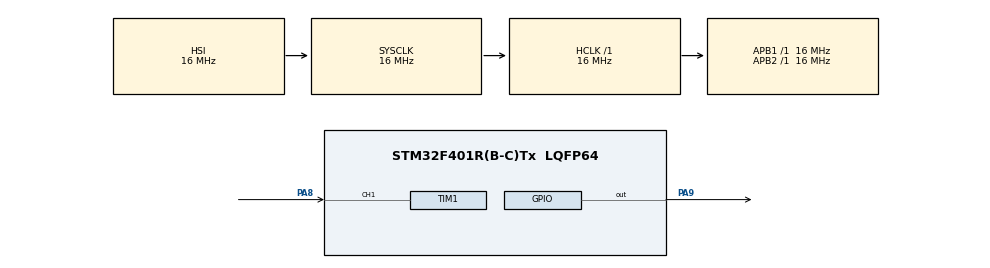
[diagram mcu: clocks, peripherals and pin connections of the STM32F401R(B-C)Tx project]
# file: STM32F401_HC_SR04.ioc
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Mcu.Family=STM32F4
Mcu.Name=STM32F401R(B-C)Tx
Mcu.Package=LQFP64
NVIC.PriorityGroup=NVIC_PRIORITYGROUP_4
NVIC.TIM1_CC_IRQn=true\:0\:0\:false\:false\:true\:true\:true\:true
PA13.Mode=Serial_Wire
PA13.Signal=SYS_JTMS-SWDIO
PA14.Mode=Serial_Wire
PA14.Signal=SYS_JTCK-SWCLK
PA8.Signal=S_TIM1_CH1
PA9.Signal=GPIO_Output
ProjectManager.HeapSize=0x200
ProjectManager.StackSize=0x400
ProjectManager.TargetToolchain=MDK-ARM V5.32
RCC.AHBFreq_Value=16000000
RCC.APB1Freq_Value=16000000
RCC.APB2Freq_Value=16000000
RCC.CortexFreq_Value=16000000
RCC.HSE_VALUE=25000000
RCC.HSI_VALUE=16000000
RCC.LSE_VALUE=32768
RCC.SYSCLKFreq_VALUE=16000000
RCC.VCOOutputFreq_Value=192000000
SH.S_TIM1_CH1.0=TIM1_CH1,Input_Capture1_from_TI1
SH.S_TIM1_CH1.1=TIM1_CH1,TriggerSource_TI1FP1
TIM1.Channel-Input_Capture1_from_TI1=TIM_CHANNEL_1
TIM1.Channel-Input_Capture2_from_TI1_63=TIM_CHANNEL_2
TIM1.ICPolarity_CH2=TIM_INPUTCHANNELPOLARITY_FALLING
TIM1.Prescaler=15
VP_TIM1_VS_ClockSourceINT.Mode=Internal
VP_TIM1_VS_ControllerModeReset.Mode=Reset Mode
VP_TIM1_VS_indirect_ch1.Mode=Input_Capture2_from_TI1_63
board=custom

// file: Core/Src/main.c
/* USER CODE BEGIN Header */
/**
  ******************************************************************************
  * @file           : main.c
  * @brief          : Main program body
  ******************************************************************************
  * @attention
  *
  * Copyright (c) 2025 STMicroelectronics.
  * All rights reserved.
  *
  * This software is licensed under terms that can be found in the LICENSE file
  * in the root directory of this software component.
  * If no LICENSE file comes with this software, it is provided AS-IS.
  *
  ******************************************************************************
  */
/* USER CODE END Header */
#include "main.h"
#include "tim.h"
#include "gpio.h"

/* USER CODE BEGIN Includes */
#include "hcsr04.h"
/* USER CODE END Includes */

void SystemClock_Config(void);
/* USER CODE BEGIN PFP */
void HAL_TIM_IC_CaptureCallback(TIM_HandleTypeDef *htim);
/* USER CODE END PFP */

int main(void)
{

  /* MCU Configuration--------------------------------------------------------*/

  /* Reset of all peripherals, Initializes the Flash interface and the Systick. */
  HAL_Init();

  /* Configure the system clock */
  SystemClock_Config();

  /* Initialize all configured peripherals */
  MX_GPIO_Init();
  MX_TIM1_Init();

  /* Infinite loop */
  /* USER CODE BEGIN WHILE */

	hcsr04_init(&htim1, GPIOA, GPIO_PIN_9, 1);
  while (1)
  {
		hcsr04_triger();
		volatile float data = hcsr04_get_cm(1000000 /* Freq that used to caculate distance*/);

    /* USER CODE END WHILE */

  }
}

void SystemClock_Config(void)
{
  RCC_OscInitTypeDef RCC_OscInitStruct = {0};
  RCC_ClkInitTypeDef RCC_ClkInitStruct = {0};

  /** Configure the main internal regulator output voltage
  */
  __HAL_RCC_PWR_CLK_ENABLE();
  __HAL_PWR_VOLTAGESCALING_CONFIG(PWR_REGULATOR_VOLTAGE_SCALE2);

  /** Initializes the RCC Oscillators according to the specified parameters
  * in the RCC_OscInitTypeDef structure.
  */
  RCC_OscInitStruct.OscillatorType = RCC_OSCILLATORTYPE_HSI;
  RCC_OscInitStruct.HSIState = RCC_HSI_ON;
  RCC_OscInitStruct.HSICalibrationValue = RCC_HSICALIBRATION_DEFAULT;
  RCC_OscInitStruct.PLL.PLLState = RCC_PLL_NONE;
  if (HAL_RCC_OscConfig(&RCC_OscInitStruct) != HAL_OK)
  {
    Error_Handler();
  }

  /** Initializes the CPU, AHB and APB buses clocks
  */
  RCC_ClkInitStruct.ClockType = RCC_CLOCKTYPE_HCLK|RCC_CLOCKTYPE_SYSCLK
                              |RCC_CLOCKTYPE_PCLK1|RCC_CLOCKTYPE_PCLK2;
  RCC_ClkInitStruct.SYSCLKSource = RCC_SYSCLKSOURCE_HSI;
  RCC_ClkInitStruct.AHBCLKDivider = RCC_SYSCLK_DIV1;
  RCC_ClkInitStruct.APB1CLKDivider = RCC_HCLK_DIV1;
  RCC_ClkInitStruct.APB2CLKDivider = RCC_HCLK_DIV1;

  if (HAL_RCC_ClockConfig(&RCC_ClkInitStruct, FLASH_LATENCY_0) != HAL_OK)
  {
    Error_Handler();
  }
}

/* USER CODE BEGIN 4 */

void HAL_TIM_IC_CaptureCallback(TIM_HandleTypeDef *htim)
{
	hcsr04_ic_handler(htim);
}

/* USER CODE END 4 */

void Error_Handler(void)
{
  __disable_irq();
  while (1)
  {
  }
}
